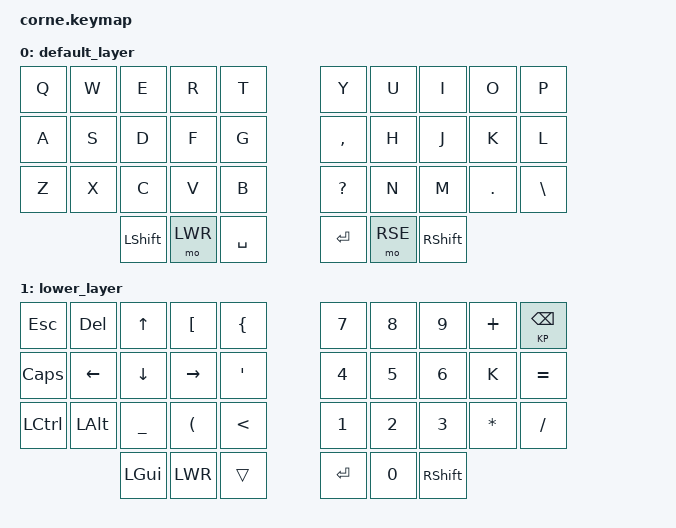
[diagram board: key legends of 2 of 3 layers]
/*
 * Copyright (c) 2020 The ZMK Contributors
 *
 * SPDX-License-Identifier: MIT
 */

#include <behaviors.dtsi>
#include <dt-bindings/zmk/keys.h>
#include <dt-bindings/zmk/bt.h>

#define DEFAULT 0
#define LWR 1
#define RSE 2

/ {
        keymap {
                compatible = "zmk,keymap";

                default_layer {
// -----------------------------------------------------------------------------------------
// |  Q  |  W  |  E  |  R  |  T  |      ##     |  Y  |  U  |  I  |  O  |  P  |
// |  A  |  S  |  D  |  F  |  G  |      ##     |  ,  |  H  |  J  |  K  |  L  |
// |  Z  |  X  |  C  |  V  |  B  |      ##     |  ?  |  N  |  M  |  .  |  \  |
//
//             | LSHFT | LWR | SPC |    ##    | ENT | RSE  | RSHFT |

            bindings = <
    &kp Q &kp W &kp E &kp R &kp T   &kp Y     &kp U     &kp I   &kp O &kp P
    &kp A &kp S &kp D &kp F &kp G   &kp COMMA &kp H     &kp J   &kp K &kp L
    &kp Z &kp X &kp C &kp V &kp B   &kp QUESTION &kp N     &kp M   &kp DOT &kp BSLH
                &kp LSHFT &mo LWR   &kp SPACE &kp RET &mo RSE &kp RSHFT
            >;
        };

                lower_layer {
// -----------------------------------------------------------------------------------------
// |  ESC    |  DEL   |   UP   |    [   |  {  |     ##     |  7  |  8  |  9  |   +  |  BKSP |
// |  CAPS   |  LEFT  |  DOWN  |  RIGHT |  '  |     ##     |  4  |  5  |  6  |   -  |   =   |
// |  LCTRL  |  LALT  |   _    |    (   |  <  |     ##     |  1  |  2  |  3  |   *  |   /   |
//
//                          GUI  |  LWR  | trans |  ##  | ENTER |  0  |  RSHFT  |

            bindings = <
    &kp ESC   &kp DEL  &kp UP    &kp LBKT   &kp LBRC  &kp N7 &kp N8 &kp N9 &kp PLUS &KP BSPC
    &kp CAPS  &kp LEFT &kp DOWN  &kp RIGHT  &kp SQT   &kp N4 &kp N5 &kp N6 &kp K    &kp EQUAL
    &kp LCTRL &kp LALT &kp UNDER &kp LPAR   &kp LT    &kp N1 &kp N2 &kp N3 &kp STAR &kp FSLH
                       &kp LGUI &kp LWR &trans    &kp RET &kp N0  &kp RSHFT
            >;
        };

                raise_layer {
// -----------------------------------------------------------------------------------------
// |  BKSP  |   %   |  `  |   ]   |  }  |    ##    |  F1   |  F2   |  F3    |   F4   |  F5  |
// |  TAB   |   &   |  $  |   @   |  "  |    ##    |  F6   |  F7   |  F8    |   F9   |  F10 |
// |  HOME  |  '|'  |  !  |   )   |  >  |    ##    |  F11  |  F12  |  PGUP  |  PGDN  |  END |
//                    GUI |  ENT  | SPC |    ##    | trans |  RSE  |  #     |
            bindings = <
    &kp BSPC &kp PRCT &kp GRAVE &kp RBKT  &kp RBRC   &kp F1  &kp F2  &kp F3    &kp F4    &KP F5
    &kp TAB  &kp LEFT &kp DOWN  &kp RIGHT &kp DQT    &kp F6  &kp F7  &kp F8    &kp F9    &kp F10
    &kp HOME &kp PIPE &kp EXCL  &kp RPAR  &kp GT     &kp f11 &kp F12 &kp PG_UP &kp PG_DN &kp END
                      &kp LGUI &kp LWR   &trans &trans &kp HASH
            >;
        };
};
